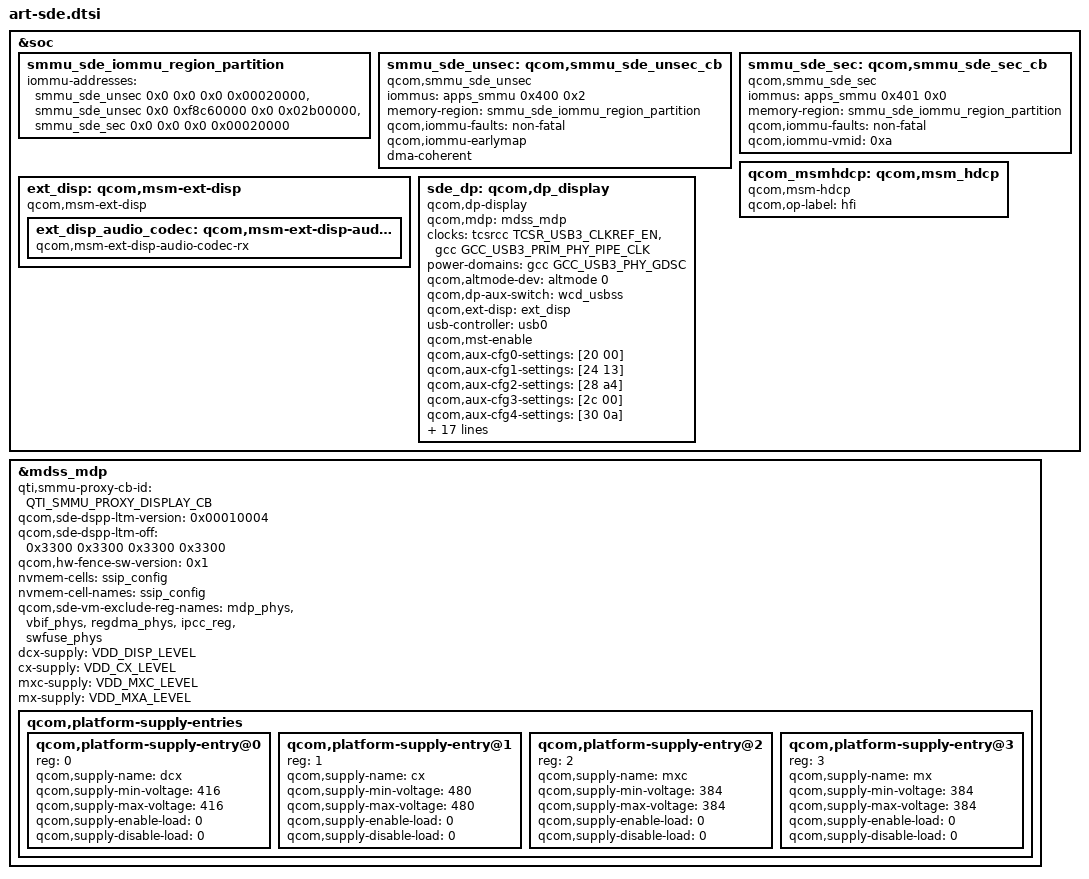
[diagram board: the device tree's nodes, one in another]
// SPDX-License-Identifier: BSD-3-Clause
/*
 * Copyright (c) Qualcomm Technologies, Inc. and/or its subsidiaries.
 */
#include <dt-bindings/arm/msm/qti-smmu-proxy-dt-ids.h>
#include <dt-bindings/clock/qcom,art-gcc.h>
#include <dt-bindings/clock/qcom,art-tcsrcc.h>
#include "art-sde-common.dtsi"

&soc {
	smmu_sde_iommu_region_partition: smmu_sde_iommu_region_partition {
		iommu-addresses = <&smmu_sde_unsec 0x0 0x0 0x0 0x00020000>,
				  <&smmu_sde_unsec 0x0 0xf8c60000  0x0 0x02b00000>,
				  <&smmu_sde_sec 0x0 0x0 0x0 0x00020000>;
	};

	smmu_sde_unsec: qcom,smmu_sde_unsec_cb {
		compatible = "qcom,smmu_sde_unsec";
		iommus = <&apps_smmu 0x400 0x2>;
		memory-region = <&smmu_sde_iommu_region_partition>;
		qcom,iommu-faults = "non-fatal";
		qcom,iommu-earlymap; /* for cont-splash */
		dma-coherent;
	};

	smmu_sde_sec: qcom,smmu_sde_sec_cb {
		compatible = "qcom,smmu_sde_sec";
		iommus = <&apps_smmu 0x401 0x0>;
		memory-region = <&smmu_sde_iommu_region_partition>;
		qcom,iommu-faults = "non-fatal";
		qcom,iommu-vmid = <0xa>;
	};

	ext_disp: qcom,msm-ext-disp {
		compatible = "qcom,msm-ext-disp";

		ext_disp_audio_codec: qcom,msm-ext-disp-audio-codec-rx {
			compatible = "qcom,msm-ext-disp-audio-codec-rx";
		};
	};

	qcom_msmhdcp: qcom,msm_hdcp {
		compatible = "qcom,msm-hdcp";
		qcom,op-label = "hfi";
		status = "ok";
	};

	sde_dp: qcom,dp_display {
		compatible = "qcom,dp-display";
		status = "ok";

		qcom,mdp = <&mdss_mdp>;

		clocks = <&tcsrcc TCSR_USB3_CLKREF_EN>,
			<&gcc GCC_USB3_PRIM_PHY_PIPE_CLK>;
		clock-names = "usb3_tcsr_clk", "usb3_pipe_clk";
		power-domains = <&gcc GCC_USB3_PHY_GDSC>;
		qcom,altmode-dev = <&altmode 0>;
		qcom,dp-aux-switch = <&wcd_usbss>;
		qcom,ext-disp = <&ext_disp>;
		usb-controller = <&usb0>;
		qcom,mst-enable;

		qcom,aux-cfg0-settings = [20 00];
		qcom,aux-cfg1-settings = [24 13];
		qcom,aux-cfg2-settings = [28 a4];
		qcom,aux-cfg3-settings = [2c 00];
		qcom,aux-cfg4-settings = [30 0a];
		qcom,aux-cfg5-settings = [34 26];
		qcom,aux-cfg6-settings = [38 0a];
		qcom,aux-cfg7-settings = [3c 03];
		qcom,aux-cfg8-settings = [40 b7];
		qcom,aux-cfg9-settings = [44 03];

		qcom,hbr-rbr-voltage-swing = <0x27 0x2f 0x36 0x3f>,
					<0x31 0x3e 0x3f 0x00>,
					<0x36 0x3f 0x00 0x00>,
					<0x3f 0x00 0x00 0x00>;
		qcom,hbr-rbr-pre-emphasis = <0x20 0x2d 0x34 0x3a>,
					<0x20 0x2e 0x35 0x00>,
					<0x20 0x2e 0x00 0x00>,
					<0x22 0x00 0x00 0x00>;

		qcom,hbr2-3-voltage-swing = <0x22 0x32 0x36 0x3a>,
					<0x29 0x39 0x3f 0x00>,
					<0x30 0x3f 0x00 0x00>,
					<0x3f 0x00 0x00 0x00>;
		qcom,hbr2-3-pre-emphasis = <0x20 0x2c 0x35 0x3b>,
					<0x22 0x2e 0x36 0x00>,
					<0x22 0x31 0x00 0x00>,
					<0x24 0x00 0x00 0x00>;
	};
};

&mdss_mdp {
	qti,smmu-proxy-cb-id = <QTI_SMMU_PROXY_DISPLAY_CB>;
	qcom,sde-dspp-ltm-version = <0x00010004>;
	/* offsets are based off dspp 0, 1, 2, and 3 */
	qcom,sde-dspp-ltm-off = <0x3300 0x3300 0x3300 0x3300>;
	qcom,hw-fence-sw-version = <0x1>;

	nvmem-cells = <&ssip_config>;
	nvmem-cell-names = "ssip_config";
	qcom,sde-vm-exclude-reg-names = "mdp_phys", "vbif_phys",
					"regdma_phys", "ipcc_reg",
					"swfuse_phys";
	dcx-supply = <&VDD_DISP_LEVEL>;
	cx-supply = <&VDD_CX_LEVEL>;
	mxc-supply = <&VDD_MXC_LEVEL>;
	mx-supply = <&VDD_MXA_LEVEL>;

	/* Pre mdss_core vregs */
	qcom,platform-supply-entries {
		#address-cells = <1>;
		#size-cells = <0>;

		qcom,platform-supply-entry@0 {
			reg = <0>;
			qcom,supply-name = "dcx";
			qcom,supply-min-voltage = <416>;
			qcom,supply-max-voltage = <416>;
			qcom,supply-enable-load = <0>;
			qcom,supply-disable-load = <0>;
		};

		qcom,platform-supply-entry@1 {
			reg = <1>;
			qcom,supply-name = "cx";
			qcom,supply-min-voltage = <480>;
			qcom,supply-max-voltage = <480>;
			qcom,supply-enable-load = <0>;
			qcom,supply-disable-load = <0>;
		};

		qcom,platform-supply-entry@2 {
			reg = <2>;
			qcom,supply-name = "mxc";
			qcom,supply-min-voltage = <384>;
			qcom,supply-max-voltage = <384>;
			qcom,supply-enable-load = <0>;
			qcom,supply-disable-load = <0>;
		};

		qcom,platform-supply-entry@3 {
			reg = <3>;
			qcom,supply-name = "mx";
			qcom,supply-min-voltage = <384>;
			qcom,supply-max-voltage = <384>;
			qcom,supply-enable-load = <0>;
			qcom,supply-disable-load = <0>;
		};
	};
};
